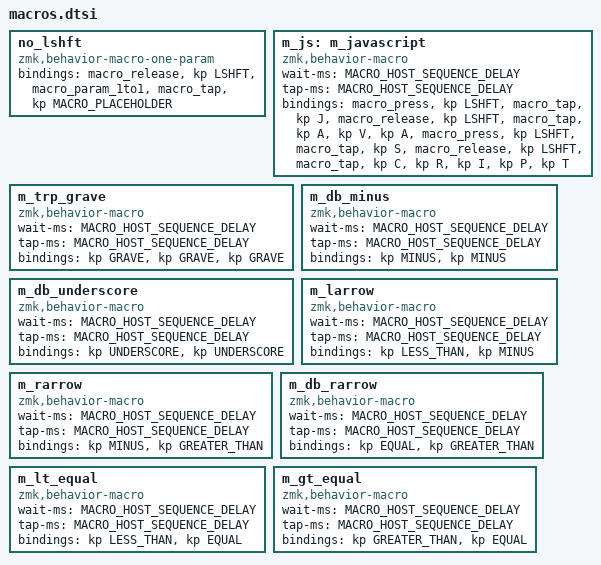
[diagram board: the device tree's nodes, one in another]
// Macro Definitions
// https://zmk.dev/docs/behaviors/macros
// https://zmk.dev/docs/config/behaviors#macro

#pragma once

// NOTE:
// Macros that send a sequence of keycodes to the connected host are recommended
// to use wait & tap time of at least 30ms to avoid keypresses being processed
// out of order.
// https://zmk.dev/docs/behaviors/macros#keycode-sequences
#define MACRO_HOST_SEQUENCE_DELAY 30


// Utility Macros
// no_lshft is my workaround for a current issue with ZMK:
// Rolled keypresses from a shifted key to a non-shifted key do not release the
// shift modifier before the non-shifted key is pressed, causing the host OS to
// register the non-shifted key as a shifted key.
// A related issue was addressed here, but doesn't fix my particular issue:
// https://github.com/zmkfirmware/zmk/pull/1828
no_lshft: no_lshft {
  compatible = "zmk,behavior-macro-one-param";
  #binding-cells = <1>;
  bindings
    = <&macro_release &kp LSHFT>
    , <&macro_param_1to1>, <&macro_tap &kp MACRO_PLACEHOLDER>;
};

// Word Macros
m_js: m_javascript {
  compatible = "zmk,behavior-macro";
  #binding-cells = <0>;
  wait-ms = <MACRO_HOST_SEQUENCE_DELAY>;
  tap-ms = <MACRO_HOST_SEQUENCE_DELAY>;
  bindings
    = <&macro_press &kp LSHFT>, <&macro_tap &kp J>, <&macro_release &kp LSHFT>
    , <&macro_tap &kp A &kp V &kp A>
    , <&macro_press &kp LSHFT>, <&macro_tap &kp S>, <&macro_release &kp LSHFT>
    , <&macro_tap &kp C &kp R &kp I &kp P &kp T>;
};


// Symbol Macros
m_trp_grave: m_trp_grave {
  compatible = "zmk,behavior-macro";
  #binding-cells = <0>;
  wait-ms = <MACRO_HOST_SEQUENCE_DELAY>;
  tap-ms = <MACRO_HOST_SEQUENCE_DELAY>;
  bindings = <&kp GRAVE>, <&kp GRAVE>, <&kp GRAVE>;
};
m_db_minus: m_db_minus {
  compatible = "zmk,behavior-macro";
  #binding-cells = <0>;
  wait-ms = <MACRO_HOST_SEQUENCE_DELAY>;
  tap-ms = <MACRO_HOST_SEQUENCE_DELAY>;
  bindings = <&kp MINUS>, <&kp MINUS>;
};
m_db_underscore: m_db_underscore {
  compatible = "zmk,behavior-macro";
  #binding-cells = <0>;
  wait-ms = <MACRO_HOST_SEQUENCE_DELAY>;
  tap-ms = <MACRO_HOST_SEQUENCE_DELAY>;
  bindings = <&kp UNDERSCORE>, <&kp UNDERSCORE>;
};
m_larrow: m_larrow {
  compatible = "zmk,behavior-macro";
  #binding-cells = <0>;
  wait-ms = <MACRO_HOST_SEQUENCE_DELAY>;
  tap-ms = <MACRO_HOST_SEQUENCE_DELAY>;
  bindings = <&kp LESS_THAN>, <&kp MINUS>;
};
m_rarrow: m_rarrow {
  compatible = "zmk,behavior-macro";
  #binding-cells = <0>;
  wait-ms = <MACRO_HOST_SEQUENCE_DELAY>;
  tap-ms = <MACRO_HOST_SEQUENCE_DELAY>;
  bindings = <&kp MINUS>, <&kp GREATER_THAN>;
};
m_db_rarrow: m_db_rarrow {
  compatible = "zmk,behavior-macro";
  #binding-cells = <0>;
  wait-ms = <MACRO_HOST_SEQUENCE_DELAY>;
  tap-ms = <MACRO_HOST_SEQUENCE_DELAY>;
  bindings = <&kp EQUAL>, <&kp GREATER_THAN>;
};
m_lt_equal: m_lt_equal {
  compatible = "zmk,behavior-macro";
  #binding-cells = <0>;
  wait-ms = <MACRO_HOST_SEQUENCE_DELAY>;
  tap-ms = <MACRO_HOST_SEQUENCE_DELAY>;
  bindings = <&kp LESS_THAN>, <&kp EQUAL>;
};
m_gt_equal: m_gt_equal {
  compatible = "zmk,behavior-macro";
  #binding-cells = <0>;
  wait-ms = <MACRO_HOST_SEQUENCE_DELAY>;
  tap-ms = <MACRO_HOST_SEQUENCE_DELAY>;
  bindings = <&kp GREATER_THAN>, <&kp EQUAL>;
};
